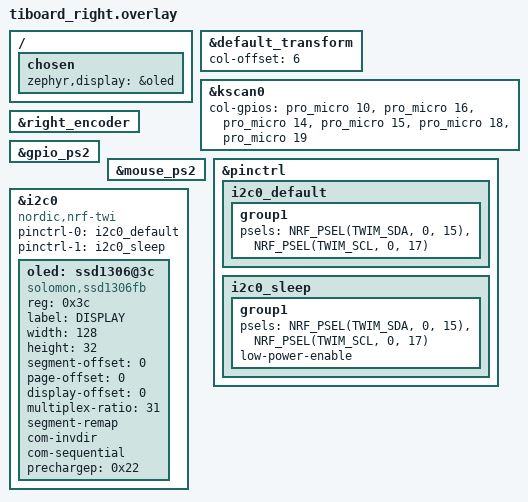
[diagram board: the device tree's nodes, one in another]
/*
 * Copyright (c) 2020 Ryan Cross
 *
 * SPDX-License-Identifier: MIT
 */

#include "tiboard.dtsi"

&default_transform {
	col-offset = <6>;
};

&kscan0 {
	col-gpios
		= <&pro_micro 10 GPIO_ACTIVE_HIGH>
		, <&pro_micro 16 GPIO_ACTIVE_HIGH>
		, <&pro_micro 14 GPIO_ACTIVE_HIGH>
		, <&pro_micro 15 GPIO_ACTIVE_HIGH>
		, <&pro_micro 18 GPIO_ACTIVE_HIGH>
		, <&pro_micro 19 GPIO_ACTIVE_HIGH>
		;
};

&right_encoder {
	status = "okay";
};

// Put this in the overlay of the central side (usually left).
// The mouse driver doesn't work on the peripheral.
// If you have your trackpoint on the right side, you need to
// make it the central side first.
//
// Check the Kconfig.defconfig and the `ZMK_SPLIT_ROLE_CENTRAL`
// setting.
&gpio_ps2 {
	status = "okay";
};

&mouse_ps2 {
	status = "okay";
};

// Adjust GPIO interrupt priority to the highest level.
// PS/2 events must be processed within 30-50us. Therefore we change the
// default gpio priority to the highest and we demote all BT interrupt
// priorities by one level.
//
// This allows the PS/2 interrupts to be triggered in time.
// &gpiote {
// 	interrupts = < 0x6 0 >;
// };


&pinctrl {
	i2c0_default: i2c0_default {
		group1 {
			psels = <NRF_PSEL(TWIM_SDA, 0, 15)>,
				<NRF_PSEL(TWIM_SCL, 0, 17)>;
		};
	};

	i2c0_sleep: i2c0_sleep {
		group1 {
			psels = <NRF_PSEL(TWIM_SDA, 0, 15)>,
				<NRF_PSEL(TWIM_SCL, 0, 17)>;
			low-power-enable;
		};
	};
};

display_i2c: &i2c0 {
    compatible = "nordic,nrf-twi";
    pinctrl-0 = <&i2c0_default>;
    pinctrl-1 = <&i2c0_sleep>;
    pinctrl-names = "default", "sleep";
 };
 
&display_i2c {
 	status = "okay";
	oled: ssd1306@3c {
		compatible = "solomon,ssd1306fb";
		reg = <0x3c>;
		label = "DISPLAY";
		width = <128>;
		height = <32>;
		segment-offset = <0>;
		page-offset = <0>;
		display-offset = <0>;
		multiplex-ratio = <31>;
		segment-remap;
		com-invdir;
		com-sequential;
		prechargep = <0x22>;
	};
};

/ {
  chosen {
    zephyr,display = &oled;
  };
};
